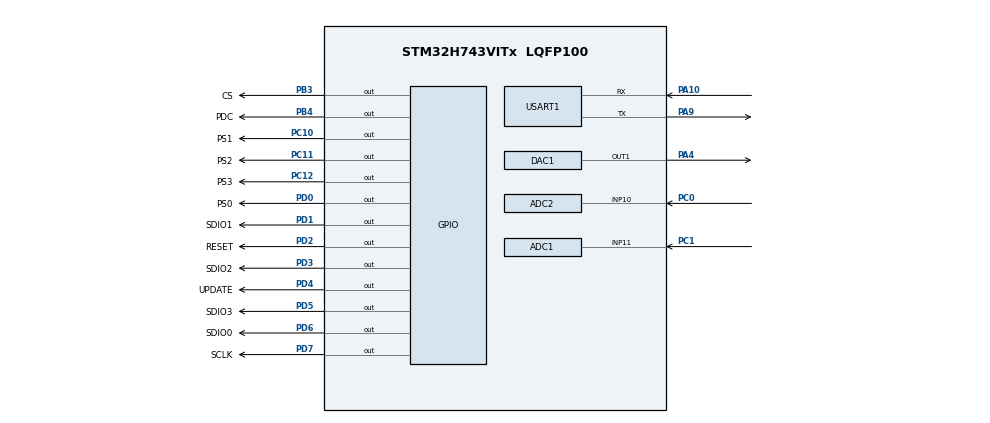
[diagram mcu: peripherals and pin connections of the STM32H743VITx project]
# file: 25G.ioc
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ADC1.Channel-2\#ChannelRegularConversion=ADC_CHANNEL_11
ADC1.ClockPrescaler=ADC_CLOCK_ASYNC_DIV1
ADC1.ContinuousConvMode=DISABLE
ADC1.ConversionDataManagement=ADC_CONVERSIONDATA_DMA_CIRCULAR
ADC1.DMAAccessModeView=ENABLE
ADC1.ExternalTrigConv=ADC_EXTERNALTRIG_T6_TRGO
ADC1.Mode=ADC_DUALMODE_REGSIMULT
ADC1.NbrOfConversionFlag=1
ADC1.OffsetNumber-2\#ChannelRegularConversion=ADC_OFFSET_NONE
ADC1.OffsetSignedSaturation-2\#ChannelRegularConversion=DISABLE
ADC1.Overrun=ADC_OVR_DATA_OVERWRITTEN
ADC1.Rank-2\#ChannelRegularConversion=1
ADC1.SamplingTime-2\#ChannelRegularConversion=ADC_SAMPLETIME_8CYCLES_5
ADC1.master=1
ADC2.Channel-0\#ChannelRegularConversion=ADC_CHANNEL_10
ADC2.ConversionDataManagement=ADC_CONVERSIONDATA_DMA_CIRCULAR
ADC2.DMAAccessModeView=ENABLE
ADC2.Mode=ADC_DUALMODE_REGSIMULT
ADC2.NbrOfConversionFlag=1
ADC2.OffsetNumber-0\#ChannelRegularConversion=ADC_OFFSET_NONE
ADC2.OffsetSignedSaturation-0\#ChannelRegularConversion=DISABLE
ADC2.Overrun=ADC_OVR_DATA_OVERWRITTEN
ADC2.Rank-0\#ChannelRegularConversion=1
ADC2.SamplingTime-0\#ChannelRegularConversion=ADC_SAMPLETIME_8CYCLES_5
CORTEX_M7.CPU_ICache=Enabled
CORTEX_M7.default_mode_Activation=1
DAC1.DAC_Channel-DAC_OUT1=DAC_CHANNEL_1
DAC1.DAC_Trigger-DAC_OUT1=DAC_TRIGGER_T7_TRGO
Dma.ADC1.0.Direction=DMA_PERIPH_TO_MEMORY
Dma.ADC1.0.EventEnable=DISABLE
Dma.ADC1.0.FIFOMode=DMA_FIFOMODE_DISABLE
Dma.ADC1.0.Instance=DMA1_Stream0
Dma.ADC1.0.MemDataAlignment=DMA_MDATAALIGN_WORD
Dma.ADC1.0.MemInc=DMA_MINC_ENABLE
Dma.ADC1.0.Mode=DMA_CIRCULAR
Dma.ADC1.0.PeriphDataAlignment=DMA_PDATAALIGN_WORD
Dma.ADC1.0.PeriphInc=DMA_PINC_DISABLE
Dma.ADC1.0.Polarity=HAL_DMAMUX_REQ_GEN_RISING
Dma.ADC1.0.Priority=DMA_PRIORITY_LOW
Dma.ADC1.0.RequestNumber=1
Dma.ADC1.0.SignalID=NONE
Dma.ADC1.0.SyncEnable=DISABLE
Dma.ADC1.0.SyncPolarity=HAL_DMAMUX_SYNC_NO_EVENT
Dma.ADC1.0.SyncRequestNumber=1
Dma.ADC1.0.SyncSignalID=NONE
Dma.ADC2.2.Direction=DMA_PERIPH_TO_MEMORY
Dma.ADC2.2.EventEnable=DISABLE
Dma.ADC2.2.FIFOMode=DMA_FIFOMODE_DISABLE
Dma.ADC2.2.Instance=DMA1_Stream1
Dma.ADC2.2.MemDataAlignment=DMA_MDATAALIGN_WORD
Dma.ADC2.2.MemInc=DMA_MINC_ENABLE
Dma.ADC2.2.Mode=DMA_CIRCULAR
Dma.ADC2.2.PeriphDataAlignment=DMA_PDATAALIGN_WORD
Dma.ADC2.2.PeriphInc=DMA_PINC_DISABLE
Dma.ADC2.2.Polarity=HAL_DMAMUX_REQ_GEN_RISING
Dma.ADC2.2.Priority=DMA_PRIORITY_LOW
Dma.ADC2.2.RequestNumber=1
Dma.ADC2.2.SignalID=NONE
Dma.ADC2.2.SyncEnable=DISABLE
Dma.ADC2.2.SyncPolarity=HAL_DMAMUX_SYNC_NO_EVENT
Dma.ADC2.2.SyncRequestNumber=1
Dma.ADC2.2.SyncSignalID=NONE
Dma.DAC1_CH1.1.Direction=DMA_MEMORY_TO_PERIPH
Dma.DAC1_CH1.1.EventEnable=DISABLE
Dma.DAC1_CH1.1.FIFOMode=DMA_FIFOMODE_DISABLE
Dma.DAC1_CH1.1.Instance=DMA1_Stream2
Dma.DAC1_CH1.1.MemDataAlignment=DMA_MDATAALIGN_HALFWORD
Dma.DAC1_CH1.1.MemInc=DMA_MINC_ENABLE
Dma.DAC1_CH1.1.Mode=DMA_CIRCULAR
Dma.DAC1_CH1.1.PeriphDataAlignment=DMA_PDATAALIGN_HALFWORD
Dma.DAC1_CH1.1.PeriphInc=DMA_PINC_DISABLE
Dma.DAC1_CH1.1.Polarity=HAL_DMAMUX_REQ_GEN_RISING
Dma.DAC1_CH1.1.Priority=DMA_PRIORITY_LOW
Dma.DAC1_CH1.1.RequestNumber=1
Dma.DAC1_CH1.1.SignalID=NONE
Dma.DAC1_CH1.1.SyncEnable=DISABLE
Dma.DAC1_CH1.1.SyncPolarity=HAL_DMAMUX_SYNC_NO_EVENT
Dma.DAC1_CH1.1.SyncRequestNumber=1
Dma.DAC1_CH1.1.SyncSignalID=NONE
Dma.Request0=ADC1
Dma.Request1=DAC1_CH1
Dma.Request2=ADC2
Mcu.Family=STM32H7
Mcu.Name=STM32H743VITx
Mcu.Package=LQFP100
NVIC.DMA1_Stream0_IRQn=true\:0\:0\:false\:false\:true\:false\:true\:true
NVIC.DMA1_Stream1_IRQn=true\:0\:0\:false\:false\:true\:false\:true\:true
NVIC.DMA1_Stream2_IRQn=true\:0\:0\:false\:false\:true\:false\:true\:true
NVIC.PriorityGroup=NVIC_PRIORITYGROUP_4
NVIC.USART1_IRQn=true\:0\:0\:false\:false\:true\:true\:true\:true
PA10.Mode=Asynchronous
PA10.Signal=USART1_RX
PA13\ (JTMS/SWDIO).Mode=Serial_Wire
PA13\ (JTMS/SWDIO).Signal=DEBUG_JTMS-SWDIO
PA14\ (JTCK/SWCLK).Mode=Serial_Wire
PA14\ (JTCK/SWCLK).Signal=DEBUG_JTCK-SWCLK
PA4.Signal=COMP_DAC11_group
PA9.Mode=Asynchronous
PA9.Signal=USART1_TX
PB3\ (JTDO/TRACESWO).GPIO_Label=CS
PB3\ (JTDO/TRACESWO).GPIO_Speed=GPIO_SPEED_FREQ_HIGH
PB3\ (JTDO/TRACESWO).PinState=GPIO_PIN_RESET
PB3\ (JTDO/TRACESWO).Signal=GPIO_Output
PB4\ (NJTRST).GPIO_Label=PDC
PB4\ (NJTRST).GPIO_Speed=GPIO_SPEED_FREQ_HIGH
PB4\ (NJTRST).Signal=GPIO_Output
PC0.Signal=ADCx_INP10
PC1.Signal=ADCx_INP11
PC10.GPIO_Label=PS1
PC10.GPIO_Speed=GPIO_SPEED_FREQ_HIGH
PC10.Signal=GPIO_Output
PC11.GPIO_Label=PS2
PC11.GPIO_Speed=GPIO_SPEED_FREQ_HIGH
PC11.Signal=GPIO_Output
PC12.GPIO_Label=PS3
PC12.GPIO_Speed=GPIO_SPEED_FREQ_HIGH
PC12.Signal=GPIO_Output
PD0.GPIO_Label=PS0
PD0.GPIO_Speed=GPIO_SPEED_FREQ_HIGH
PD0.Signal=GPIO_Output
PD1.GPIO_Label=SDIO1
PD1.GPIO_Speed=GPIO_SPEED_FREQ_HIGH
PD1.Signal=GPIO_Output
PD2.GPIO_Label=RESET
PD2.GPIO_Speed=GPIO_SPEED_FREQ_HIGH
PD2.Signal=GPIO_Output
PD3.GPIO_Label=SDIO2
PD3.GPIO_Speed=GPIO_SPEED_FREQ_HIGH
PD3.Signal=GPIO_Output
PD4.GPIO_Label=UPDATE
PD4.GPIO_Speed=GPIO_SPEED_FREQ_HIGH
PD4.Signal=GPIO_Output
PD5.GPIO_Label=SDIO3
PD5.Signal=GPIO_Output
PD6.GPIO_Label=SDIO0
PD6.Signal=GPIO_Output
PD7.GPIO_Label=SCLK
PD7.Signal=GPIO_Output
PH0-OSC_IN\ (PH0).Mode=HSE-External-Oscillator
PH0-OSC_IN\ (PH0).Signal=RCC_OSC_IN
PH1-OSC_OUT\ (PH1).Mode=HSE-External-Oscillator
PH1-OSC_OUT\ (PH1).Signal=RCC_OSC_OUT
ProjectManager.HeapSize=0x200
ProjectManager.StackSize=0x6000
ProjectManager.TargetToolchain=CMake
RCC.ADCFreq_Value=36000000
RCC.APB1Freq_Value=120000000
RCC.APB2Freq_Value=120000000
RCC.APB3Freq_Value=120000000
RCC.APB4Freq_Value=120000000
RCC.CortexFreq_Value=480000000
RCC.D1PPRE=RCC_APB3_DIV2
RCC.D2PPRE1=RCC_APB1_DIV2
RCC.D2PPRE2=RCC_APB2_DIV2
RCC.D3PPRE=RCC_APB4_DIV2
RCC.DIVM1=4
RCC.DIVN1=60
RCC.DIVN2=252
RCC.DIVP2=14
RCC.DIVQ1=12
RCC.HCLKFreq_Value=240000000
RCC.HPRE=RCC_HCLK_DIV2
RCC.HSE_Timout=100
RCC.PLL2FRACN=0
RCC.PLL3FRACN=0
RCC.PLLFRACN=0
RCC.PWR_Regulator_Voltage_Scale=PWR_REGULATOR_VOLTAGE_SCALE0
RCC.RCC_MCO2Source=RCC_MCO2SOURCE_HSE
RCC.SYSCLKFreq_VALUE=480000000
RCC.SYSCLKSource=RCC_SYSCLKSOURCE_PLLCLK
RCC.USBFreq_Value=80000000
SH.ADCx_INP10.0=ADC2_INP10,IN10-Single-Ended
SH.ADCx_INP11.0=ADC1_INP11,IN11-Single-Ended
SH.COMP_DAC11_group.0=DAC1_OUT1,DAC_OUT1
TIM6.AutoReloadPreload=TIM_AUTORELOAD_PRELOAD_ENABLE
TIM6.Period=291
TIM6.TIM_MasterOutputTrigger=TIM_TRGO_UPDATE
TIM7.AutoReloadPreload=TIM_AUTORELOAD_PRELOAD_ENABLE
TIM7.Period=145
TIM7.TIM_MasterOutputTrigger=TIM_TRGO_UPDATE
USART1.VirtualMode-Asynchronous=VM_ASYNC
VP_MEMORYMAP_VS_MEMORYMAP.Mode=CurAppReg
VP_TIM6_VS_ClockSourceINT.Mode=Enable_Timer
VP_TIM7_VS_ClockSourceINT.Mode=Enable_Timer
board=custom

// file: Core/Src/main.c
/* USER CODE BEGIN Header */
/**
 ******************************************************************************
 * @file           : main.c
 * @brief          : Main program body
 ******************************************************************************
 * @attention
 *
 * Copyright (c) 2026 STMicroelectronics.
 * All rights reserved.
 *
 * This software is licensed under terms that can be found in the LICENSE file
 * in the root directory of this software component.
 * If no LICENSE file comes with this software, it is provided AS-IS.
 *
 ******************************************************************************
 */
/* USER CODE END Header */
#include "main.h"
#include "adc.h"
#include "dac.h"
#include "dma.h"
#include "tim.h"
#include "usart.h"
#include "gpio.h"

/* USER CODE BEGIN Includes */
#include "app_state.h"
#include "AD9959.h"
/* USER CODE END Includes */

void SystemClock_Config(void);
void PeriphCommonClock_Config(void);
static void MPU_Config(void);

int main(void)
{

    /* MPU Configuration--------------------------------------------------------*/
    MPU_Config();

    /* Enable the CPU Cache */

    /* Enable I-Cache---------------------------------------------------------*/
    SCB_EnableICache();

    /* MCU Configuration--------------------------------------------------------*/

    /* Reset of all peripherals, Initializes the Flash interface and the Systick. */
    HAL_Init();

    /* Configure the system clock */
    SystemClock_Config();

    /* Configure the peripherals common clocks */
    PeriphCommonClock_Config();

    /* Initialize all configured peripherals */
    MX_GPIO_Init();
    MX_DMA_Init();
    MX_USART1_UART_Init();
    MX_ADC1_Init();
    MX_TIM6_Init();
    MX_ADC2_Init();
    MX_DAC1_Init();
    MX_TIM7_Init();
    /* USER CODE BEGIN 2 */
    app_init();

    Write_frequency(3, 1000);
    Write_Amplitude(3, 1023);
    /* USER CODE END 2 */

    /* Infinite loop */
    /* USER CODE BEGIN WHILE */
    while (1)
    {
        app_poll();
        /* USER CODE END WHILE */

    }
}

void SystemClock_Config(void)
{
    RCC_OscInitTypeDef RCC_OscInitStruct = {0};
    RCC_ClkInitTypeDef RCC_ClkInitStruct = {0};

    /** Supply configuration update enable
     */
    HAL_PWREx_ConfigSupply(PWR_LDO_SUPPLY);

    /** Configure the main internal regulator output voltage
     */
    __HAL_PWR_VOLTAGESCALING_CONFIG(PWR_REGULATOR_VOLTAGE_SCALE0);

    while (!__HAL_PWR_GET_FLAG(PWR_FLAG_VOSRDY))
    {
    }

    /** Initializes the RCC Oscillators according to the specified parameters
     * in the RCC_OscInitTypeDef structure.
     */
    RCC_OscInitStruct.OscillatorType = RCC_OSCILLATORTYPE_HSI;
    RCC_OscInitStruct.HSIState = RCC_HSI_DIV1;
    RCC_OscInitStruct.HSICalibrationValue = RCC_HSICALIBRATION_DEFAULT;
    RCC_OscInitStruct.PLL.PLLState = RCC_PLL_ON;
    RCC_OscInitStruct.PLL.PLLSource = RCC_PLLSOURCE_HSI;
    RCC_OscInitStruct.PLL.PLLM = 4;
    RCC_OscInitStruct.PLL.PLLN = 60;
    RCC_OscInitStruct.PLL.PLLP = 2;
    RCC_OscInitStruct.PLL.PLLQ = 12;
    RCC_OscInitStruct.PLL.PLLR = 2;
    RCC_OscInitStruct.PLL.PLLRGE = RCC_PLL1VCIRANGE_3;
    RCC_OscInitStruct.PLL.PLLVCOSEL = RCC_PLL1VCOWIDE;
    RCC_OscInitStruct.PLL.PLLFRACN = 0;
    if (HAL_RCC_OscConfig(&RCC_OscInitStruct) != HAL_OK)
    {
        Error_Handler();
    }

    /** Initializes the CPU, AHB and APB buses clocks
     */
    RCC_ClkInitStruct.ClockType = RCC_CLOCKTYPE_HCLK | RCC_CLOCKTYPE_SYSCLK | RCC_CLOCKTYPE_PCLK1 |
                                  RCC_CLOCKTYPE_PCLK2 | RCC_CLOCKTYPE_D3PCLK1 | RCC_CLOCKTYPE_D1PCLK1;
    RCC_ClkInitStruct.SYSCLKSource = RCC_SYSCLKSOURCE_PLLCLK;
    RCC_ClkInitStruct.SYSCLKDivider = RCC_SYSCLK_DIV1;
    RCC_ClkInitStruct.AHBCLKDivider = RCC_HCLK_DIV2;
    RCC_ClkInitStruct.APB3CLKDivider = RCC_APB3_DIV2;
    RCC_ClkInitStruct.APB1CLKDivider = RCC_APB1_DIV2;
    RCC_ClkInitStruct.APB2CLKDivider = RCC_APB2_DIV2;
    RCC_ClkInitStruct.APB4CLKDivider = RCC_APB4_DIV2;

    if (HAL_RCC_ClockConfig(&RCC_ClkInitStruct, FLASH_LATENCY_4) != HAL_OK)
    {
        Error_Handler();
    }
}

void PeriphCommonClock_Config(void)
{
    RCC_PeriphCLKInitTypeDef PeriphClkInitStruct = {0};

    /** Initializes the peripherals clock
     */
    PeriphClkInitStruct.PeriphClockSelection = RCC_PERIPHCLK_ADC;
    PeriphClkInitStruct.PLL2.PLL2M = 32;
    PeriphClkInitStruct.PLL2.PLL2N = 252;
    PeriphClkInitStruct.PLL2.PLL2P = 14;
    PeriphClkInitStruct.PLL2.PLL2Q = 2;
    PeriphClkInitStruct.PLL2.PLL2R = 2;
    PeriphClkInitStruct.PLL2.PLL2RGE = RCC_PLL2VCIRANGE_1;
    PeriphClkInitStruct.PLL2.PLL2VCOSEL = RCC_PLL2VCOWIDE;
    PeriphClkInitStruct.PLL2.PLL2FRACN = 0;
    PeriphClkInitStruct.AdcClockSelection = RCC_ADCCLKSOURCE_PLL2;
    if (HAL_RCCEx_PeriphCLKConfig(&PeriphClkInitStruct) != HAL_OK)
    {
        Error_Handler();
    }
}

/* MPU Configuration */

void MPU_Config(void)
{
    MPU_Region_InitTypeDef MPU_InitStruct = {0};

    /* Disables the MPU */
    HAL_MPU_Disable();

    /** Initializes and configures the Region and the memory to be protected
     */
    MPU_InitStruct.Enable = MPU_REGION_ENABLE;
    MPU_InitStruct.Number = MPU_REGION_NUMBER0;
    MPU_InitStruct.BaseAddress = 0x0;
    MPU_InitStruct.Size = MPU_REGION_SIZE_4GB;
    MPU_InitStruct.SubRegionDisable = 0x87;
    MPU_InitStruct.TypeExtField = MPU_TEX_LEVEL0;
    MPU_InitStruct.AccessPermission = MPU_REGION_NO_ACCESS;
    MPU_InitStruct.DisableExec = MPU_INSTRUCTION_ACCESS_DISABLE;
    MPU_InitStruct.IsShareable = MPU_ACCESS_SHAREABLE;
    MPU_InitStruct.IsCacheable = MPU_ACCESS_NOT_CACHEABLE;
    MPU_InitStruct.IsBufferable = MPU_ACCESS_NOT_BUFFERABLE;

    HAL_MPU_ConfigRegion(&MPU_InitStruct);
    /* Enables the MPU */
    HAL_MPU_Enable(MPU_PRIVILEGED_DEFAULT);
}

void Error_Handler(void)
{
    __disable_irq();
    while (1)
    {
    }
}
#ifdef USE_FULL_ASSERT
/**
 * @brief  Reports the name of the source file and the source line number
 *         where the assert_param error has occurred.
 * @param  file: pointer to the source file name
 * @param  line: assert_param error line source number
 * @retval None
 */
void assert_failed(uint8_t *file, uint32_t line)
{
    /* USER CODE BEGIN 6 */
    /* User can add his own implementation to report the file name and line
       number, ex: printf("Wrong parameters value: file %s on line %d\r\n", file,
       line) */
    /* USER CODE END 6 */
}
#endif /* USE_FULL_ASSERT */
